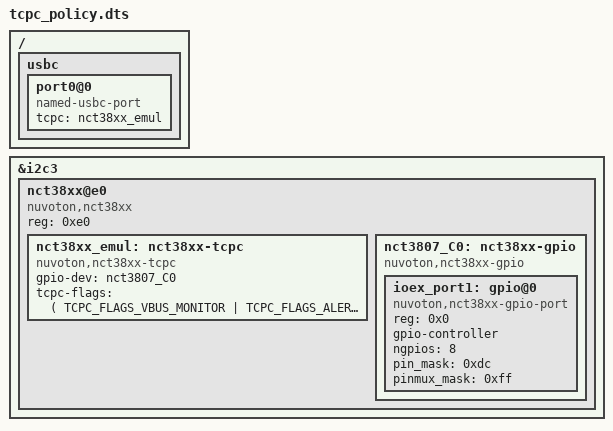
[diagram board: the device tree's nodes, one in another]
/* Copyright 2022 The ChromiumOS Authors
 * Use of this source code is governed by a BSD-style license that can be
 * found in the LICENSE file.
 */

#include <dt-bindings/usb_pd_tcpm.h>

/ {
	usbc {
		port0@0 {
			compatible = "named-usbc-port";
			tcpc = <&nct38xx_emul>;
		};
	};
};

&i2c3 {
	status="okay";

	nct38xx@e0 {
		compatible = "nuvoton,nct38xx";
		reg = <0xe0>;

		nct38xx_emul: nct38xx-tcpc {
			compatible = "nuvoton,nct38xx-tcpc";
			gpio-dev = < &nct3807_C0 >;
			tcpc-flags = <(
				TCPC_FLAGS_VBUS_MONITOR |
				TCPC_FLAGS_ALERT_OD |
				TCPC_FLAGS_CONTROL_VCONN |
				TCPC_FLAGS_CONTROL_FRS)>;
		};

		nct3807_C0: nct38xx-gpio {
			#address-cells = <1>;
			#size-cells = <0>;
			compatible = "nuvoton,nct38xx-gpio";

			ioex_port1: gpio@0 {
				compatible = "nuvoton,nct38xx-gpio-port";
				reg = <0x0>;
				gpio-controller;
				#gpio-cells = <2>;
				ngpios = <8>;
				pin_mask = <0xdc>;
				pinmux_mask = <0xff>;
			};
		};
	};
};
